VERSION "created by canmatrix"

NS_ :

BS_:

BU_: User ADM_PC_LL25 ADM_PC_BC25 ADM_PC_BP25 ADM_PC_BI25

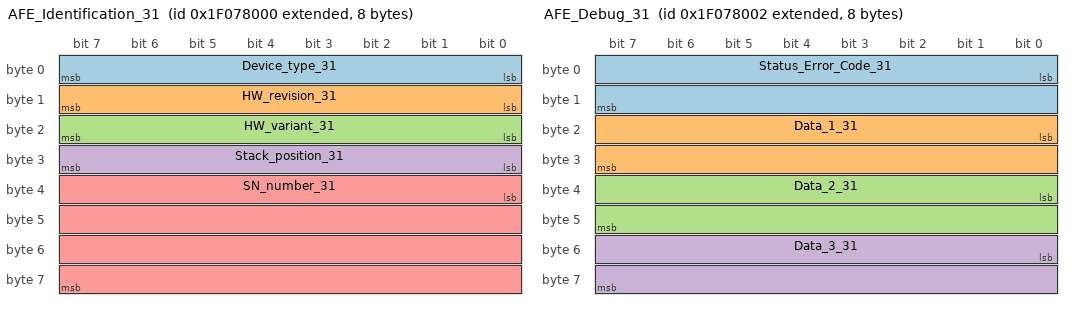
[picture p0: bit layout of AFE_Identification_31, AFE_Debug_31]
BO_ 2668068864 AFE_Identification_31: 8 ADM_PC_BP25
 SG_ Device_type_31 : 0|8@1+ (1,0) [0|255] "" Vector__XXX
 SG_ HW_revision_31 : 8|8@1+ (1,0) [0|255] "" Vector__XXX
 SG_ HW_variant_31 : 16|8@1+ (1,0) [0|255] "" Vector__XXX
 SG_ Stack_position_31 : 24|8@1+ (1,0) [0|255] "" Vector__XXX
 SG_ SN_number_31 : 32|32@1+ (1,0) [0|4294967295] "" Vector__XXX

BO_ 2668068865 AFE_FwInfo_31: 8 ADM_PC_BP25
 SG_ FW_info_mux_31 M : 56|8@1+ (1,0) [0|255] "" Vector__XXX
 SG_ FW_revision_0_31 m0 : 0|8@1+ (1,0) [0|255] "" Vector__XXX
 SG_ FW_revision_1_31 m0 : 8|8@1+ (1,0) [0|255] "" Vector__XXX
 SG_ FW_revision_2_31 m0 : 16|8@1+ (1,0) [0|255] "" Vector__XXX
 SG_ FW_revision_3_31 m0 : 24|8@1+ (1,0) [0|255] "" Vector__XXX
 SG_ FW_revision_4_31 m0 : 32|8@1+ (1,0) [0|255] "" Vector__XXX
 SG_ FW_revision_5_31 m0 : 40|8@1+ (1,0) [0|255] "" Vector__XXX
 SG_ FW_revision_6_31 m0 : 48|8@1+ (1,0) [0|255] "" Vector__XXX
 SG_ FW_revision_7_31 m1 : 0|8@1+ (1,0) [0|255] "" Vector__XXX
 SG_ FW_revision_8_31 m1 : 8|8@1+ (1,0) [0|255] "" Vector__XXX
 SG_ FW_revision_9_31 m1 : 16|8@1+ (1,0) [0|255] "" Vector__XXX
 SG_ FW_revision_10_31 m1 : 24|8@1+ (1,0) [0|255] "" Vector__XXX
 SG_ FW_revision_11_31 m1 : 32|8@1+ (1,0) [0|255] "" Vector__XXX
 SG_ FW_revision_12_31 m1 : 40|8@1+ (1,0) [0|255] "" Vector__XXX
 SG_ FW_revision_13_31 m1 : 48|8@1+ (1,0) [0|255] "" Vector__XXX
 SG_ FW_datecode_0_31 m2 : 0|8@1+ (1,0) [0|255] "" Vector__XXX
 SG_ FW_datecode_1_31 m2 : 8|8@1+ (1,0) [0|255] "" Vector__XXX
 SG_ FW_datecode_2_31 m2 : 16|8@1+ (1,0) [0|255] "" Vector__XXX
 SG_ FW_datecode_3_31 m2 : 24|8@1+ (1,0) [0|255] "" Vector__XXX
 SG_ FW_datecode_4_31 m2 : 32|8@1+ (1,0) [0|255] "" Vector__XXX
 SG_ FW_datecode_5_31 m2 : 40|8@1+ (1,0) [0|255] "" Vector__XXX
 SG_ FW_datecode_6_31 m2 : 48|8@1+ (1,0) [0|255] "" Vector__XXX
 SG_ FW_datecode_7_31 m3 : 0|8@1+ (1,0) [0|255] "" Vector__XXX
 SG_ FW_datecode_8_31 m3 : 8|8@1+ (1,0) [0|255] "" Vector__XXX
 SG_ FW_datecode_9_31 m3 : 16|8@1+ (1,0) [0|255] "" Vector__XXX
 SG_ FW_datecode_10_31 m3 : 24|8@1+ (1,0) [0|255] "" Vector__XXX
 SG_ FW_datecode_11_31 m3 : 32|8@1+ (1,0) [0|255] "" Vector__XXX
 SG_ FW_datecode_12_31 m3 : 40|8@1+ (1,0) [0|255] "" Vector__XXX
 SG_ FW_datecode_13_31 m3 : 48|8@1+ (1,0) [0|255] "" Vector__XXX

BO_ 2668068877 _AFE_Boot_FwInfo_31: 8 ADM_PC_BP25
 SG_ Boot_FW_info_mux_31 M : 56|8@1+ (1,0) [0|255] "" Vector__XXX
 SG_ FW_revision_0_31 m0 : 0|8@1+ (1,0) [0|255] "" Vector__XXX
 SG_ FW_revision_1_31 m0 : 8|8@1+ (1,0) [0|255] "" Vector__XXX
 SG_ FW_revision_2_31 m0 : 16|8@1+ (1,0) [0|255] "" Vector__XXX
 SG_ FW_revision_3_31 m0 : 24|8@1+ (1,0) [0|255] "" Vector__XXX
 SG_ FW_revision_4_31 m0 : 32|8@1+ (1,0) [0|255] "" Vector__XXX
 SG_ FW_revision_5_31 m0 : 40|8@1+ (1,0) [0|255] "" Vector__XXX
 SG_ FW_revision_6_31 m0 : 48|8@1+ (1,0) [0|255] "" Vector__XXX
 SG_ FW_revision_7_31 m1 : 0|8@1+ (1,0) [0|255] "" Vector__XXX
 SG_ FW_revision_8_31 m1 : 8|8@1+ (1,0) [0|255] "" Vector__XXX
 SG_ FW_revision_9_31 m1 : 16|8@1+ (1,0) [0|255] "" Vector__XXX
 SG_ FW_revision_10_31 m1 : 24|8@1+ (1,0) [0|255] "" Vector__XXX
 SG_ FW_revision_11_31 m1 : 32|8@1+ (1,0) [0|255] "" Vector__XXX
 SG_ FW_revision_12_31 m1 : 40|8@1+ (1,0) [0|255] "" Vector__XXX
 SG_ FW_revision_13_31 m1 : 48|8@1+ (1,0) [0|255] "" Vector__XXX
 SG_ FW_datecode_0_31 m2 : 0|8@1+ (1,0) [0|255] "" Vector__XXX
 SG_ FW_datecode_1_31 m2 : 8|8@1+ (1,0) [0|255] "" Vector__XXX
 SG_ FW_datecode_2_31 m2 : 16|8@1+ (1,0) [0|255] "" Vector__XXX
 SG_ FW_datecode_3_31 m2 : 24|8@1+ (1,0) [0|255] "" Vector__XXX
 SG_ FW_datecode_4_31 m2 : 32|8@1+ (1,0) [0|255] "" Vector__XXX
 SG_ FW_datecode_5_31 m2 : 40|8@1+ (1,0) [0|255] "" Vector__XXX
 SG_ FW_datecode_6_31 m2 : 48|8@1+ (1,0) [0|255] "" Vector__XXX
 SG_ FW_datecode_7_31 m3 : 0|8@1+ (1,0) [0|255] "" Vector__XXX
 SG_ FW_datecode_8_31 m3 : 8|8@1+ (1,0) [0|255] "" Vector__XXX
 SG_ FW_datecode_9_31 m3 : 16|8@1+ (1,0) [0|255] "" Vector__XXX
 SG_ FW_datecode_10_31 m3 : 24|8@1+ (1,0) [0|255] "" Vector__XXX
 SG_ FW_datecode_11_31 m3 : 32|8@1+ (1,0) [0|255] "" Vector__XXX
 SG_ FW_datecode_12_31 m3 : 40|8@1+ (1,0) [0|255] "" Vector__XXX
 SG_ FW_datecode_13_31 m3 : 48|8@1+ (1,0) [0|255] "" Vector__XXX

BO_ 2668068866 AFE_Debug_31: 8 ADM_PC_BP25
 SG_ Status_Error_Code_31 : 0|16@1+ (1,0) [0|65535] "" Vector__XXX
 SG_ Data_1_31 : 16|16@1+ (1,0) [0|65535] "" Vector__XXX
 SG_ Data_2_31 : 32|16@1+ (1,0) [0|65535] "" Vector__XXX
 SG_ Data_3_31 : 48|16@1+ (1,0) [0|65535] "" Vector__XXX

BO_ 2668068871 AFE_Status_31: 8 ADM_PC_BP25
 SG_ Running_31 : 0|1@1+ (1,0) [0|1] "" Vector__XXX
 SG_ PWM_31 : 1|1@1+ (1,0) [0|1] "" Vector__XXX
 SG_ Current_dc_loop_mode_31 : 2|1@1+ (1,0) [0|1] "" Vector__XXX
 SG_ Current_ac_loop_mode_31 : 3|1@1+ (1,0) [0|1] "" Vector__XXX
 SG_ Buck_31 : 5|1@1+ (1,0) [0|1] "" Vector__XXX
 SG_ Boost_31 : 6|1@1+ (1,0) [0|1] "" Vector__XXX
 SG_ Precharge_dc_buck_mode_31 : 7|1@1+ (1,0) [0|1] "" Vector__XXX
 SG_ Precharge_dc_boost_mode_31 : 8|1@1+ (1,0) [0|1] "" Vector__XXX
 SG_ Rectifier_3ph_31 : 9|1@1+ (1,0) [0|1] "" Vector__XXX
 SG_ Stack_mode_31 : 10|1@1+ (1,0) [0|1] "" Vector__XXX
 SG_ Master_31 : 11|1@1+ (1,0) [0|1] "" Vector__XXX
 SG_ Slave_31 : 12|1@1+ (1,0) [0|1] "" Vector__XXX
 SG_ Inverter_1ph_31 : 13|1@1+ (1,0) [0|1] "" Vector__XXX
 SG_ Boost_Neutral_31 : 14|1@1+ (1,0) [0|1] "" Vector__XXX
 SG_ Rectifier_1ph_31 : 15|1@1+ (1,0) [0|1] "" Vector__XXX
 SG_ Inverter_3ph_31 : 16|1@1+ (1,0) [0|1] "" Vector__XXX
 SG_ Ready_31 : 17|1@1+ (1,0) [0|1] "" Vector__XXX
 SG_ Inverter_1ph_Sync_31 : 18|1@1+ (1,0) [0|1] "" Vector__XXX
 SG_ Neutral_31 : 19|1@1+ (1,0) [0|1] "" Vector__XXX
 SG_ Rectifier_1ph_Buck_31 : 20|1@1+ (1,0) [0|1] "" Vector__XXX
 SG_ Inverter_1ph_Boost_31 : 21|1@1+ (1,0) [0|1] "" Vector__XXX
 SG_ Rectifier_distributed_31 : 22|1@1+ (1,0) [0|1] "" Vector__XXX
 SG_ MPPT_buck_31 : 23|1@1+ (1,0) [0|1] "" Vector__XXX
 SG_ MPPT_boost_31 : 24|1@1+ (1,0) [0|1] "" Vector__XXX
 SG_ Buck_2p_float_31 : 25|1@1+ (1,0) [0|1] "" Vector__XXX
 SG_ Inverter_1ph_Distributed_31 : 26|1@1+ (1,0) [0|1] "" Vector__XXX

BO_ 2668068870 AFE_Faults_31: 3 ADM_PC_BP25
 SG_ Protection_trip_internal_31 : 0|1@1+ (1,0) [0|1] "" Vector__XXX
 SG_ Protection_trip_external_31 : 1|1@1+ (1,0) [0|1] "" Vector__XXX
 SG_ Phase_U_overcurrent_31 : 2|1@1+ (1,0) [0|1] "" Vector__XXX
 SG_ Phase_U_overvoltage_31 : 3|1@1+ (1,0) [0|1] "" Vector__XXX
 SG_ Phase_U_undervoltage_31 : 4|1@1+ (1,0) [0|1] "" Vector__XXX
 SG_ Phase_V_overvoltage_31 : 5|1@1+ (1,0) [0|1] "" Vector__XXX
 SG_ Phase_V_undervoltage_31 : 6|1@1+ (1,0) [0|1] "" Vector__XXX
 SG_ Phase_V_overcurrent_31 : 7|1@1+ (1,0) [0|1] "" Vector__XXX
 SG_ Phase_W_overvoltage_31 : 8|1@1+ (1,0) [0|1] "" Vector__XXX
 SG_ Phase_W_undervoltage_31 : 9|1@1+ (1,0) [0|1] "" Vector__XXX
 SG_ Phase_W_overcurrent_31 : 10|1@1+ (1,0) [0|1] "" Vector__XXX
 SG_ DC_undervoltage_31 : 11|1@1+ (1,0) [0|1] "" Vector__XXX
 SG_ DC_overvoltage_31 : 12|1@1+ (1,0) [0|1] "" Vector__XXX
 SG_ MOSFET_overtemperature_31 : 13|1@1+ (1,0) [0|1] "" Vector__XXX
 SG_ Inductor_overtemperature_31 : 14|1@1+ (1,0) [0|1] "" Vector__XXX
 SG_ Keep_Alive_not_served_31 : 15|1@1+ (1,0) [0|1] "" Vector__XXX
 SG_ PLL_not_locked_31 : 16|1@1+ (1,0) [0|1] "" Vector__XXX
 SG_ NFO_31 : 20|1@1+ (1,0) [0|1] "" Vector__XXX
 SG_ Measurement_system_failure_31 : 21|1@1+ (1,0) [0|1] "" Vector__XXX
 SG_ EEPROM_failure_31 : 22|1@1+ (1,0) [0|1] "" Vector__XXX
 SG_ System_31 : 23|1@1+ (1,0) [0|1] "" Vector__XXX

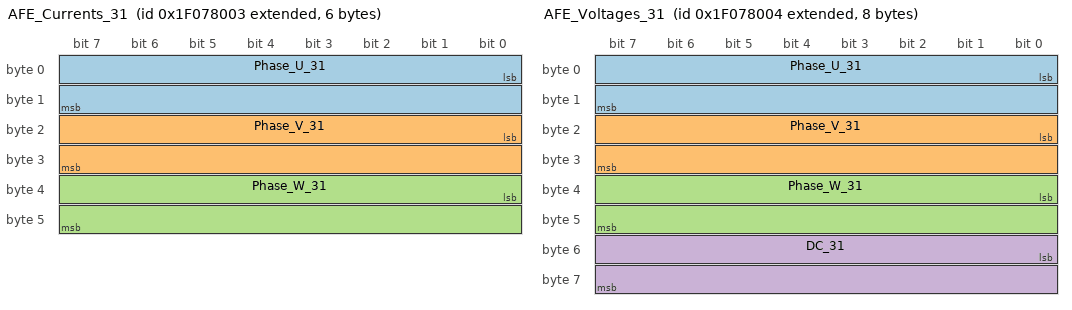
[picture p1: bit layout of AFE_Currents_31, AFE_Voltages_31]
BO_ 2668068867 AFE_Currents_31: 6 ADM_PC_BP25
 SG_ Phase_U_31 : 0|16@1- (0.01,0) [-327.68|327.67] "A" Vector__XXX
 SG_ Phase_V_31 : 16|16@1- (0.01,0) [-327.68|327.67] "A" Vector__XXX
 SG_ Phase_W_31 : 32|16@1- (0.01,0) [-327.68|327.67] "A" Vector__XXX

BO_ 2668068880 AFE_DC_Bus_current_31: 2 ADM_PC_BP25
 SG_ Bus_current_31 : 0|16@1- (0.01,0) [-327.68|327.67] "A" Vector__XXX

BO_ 2668068878 _AFE_Broadcast_31: 8 ADM_PC_BP25
 SG_ Diagnostics_Index_31 M : 56|8@1+ (1,0) [0|255] "" Vector__XXX
 SG_ Phase_U_31 m1 : 8|16@1- (0.01,0) [-327.68|327.67] "A" ADM_PC_BP25
 SG_ Phase_V_31 m1 : 24|16@1- (0.01,0) [-327.68|327.67] "A" ADM_PC_BP25
 SG_ Phase_W_31 m1 : 40|16@1- (0.01,0) [-327.68|327.67] "A" ADM_PC_BP25
 SG_ Stack_position_31 : 0|5@1+ (1,0) [0|31] "" ADM_PC_BP25
 SG_ Group_ID_31 : 5|3@1+ (1,0) [0|7] "" ADM_PC_BP25

BO_ 2668068868 AFE_Voltages_31: 8 ADM_PC_BP25
 SG_ Phase_U_31 : 0|16@1- (0.1,0) [-3276.8|3276.7] "V" Vector__XXX
 SG_ Phase_V_31 : 16|16@1- (0.1,0) [-3276.8|3276.7] "V" Vector__XXX
 SG_ Phase_W_31 : 32|16@1- (0.1,0) [-3276.8|3276.7] "V" Vector__XXX
 SG_ DC_31 : 48|16@1- (0.1,0) [-3276.8|3276.7] "V" Vector__XXX

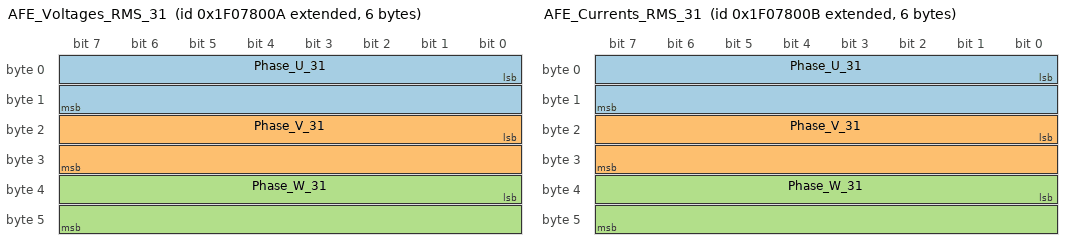
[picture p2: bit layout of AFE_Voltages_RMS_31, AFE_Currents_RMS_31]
BO_ 2668068874 AFE_Voltages_RMS_31: 6 ADM_PC_BP25
 SG_ Phase_U_31 : 0|16@1+ (0.1,0) [0|6553.5] "V" Vector__XXX
 SG_ Phase_V_31 : 16|16@1+ (0.1,0) [0|6553.5] "V" Vector__XXX
 SG_ Phase_W_31 : 32|16@1+ (0.1,0) [0|6553.5] "V" Vector__XXX

BO_ 2668068875 AFE_Currents_RMS_31: 6 ADM_PC_BP25
 SG_ Phase_U_31 : 0|16@1+ (0.01,0) [0.00|655.35] "A" Vector__XXX
 SG_ Phase_V_31 : 16|16@1+ (0.01,0) [0.00|655.35] "A" Vector__XXX
 SG_ Phase_W_31 : 32|16@1+ (0.01,0) [0.00|655.35] "A" Vector__XXX

BO_ 2668068876 AFE_Mains_31: 4 ADM_PC_BP25
 SG_ Frequency_31 : 0|16@1+ (0.01,0) [0.00|655.35] "Hz" Vector__XXX
 SG_ Phase_31 : 16|16@1- (0.1,0) [-3276.8|3276.7] "Deg." Vector__XXX

BO_ 2668068869 AFE_Temperatures_31: 4 ADM_PC_BP25
 SG_ Temp_Bridge_31 : 0|16@1- (0.01,0) [-327.68|327.67] "°C" Vector__XXX
 SG_ Temp_Inductors_31 : 16|16@1- (0.01,0) [-327.68|327.67] "°C" Vector__XXX

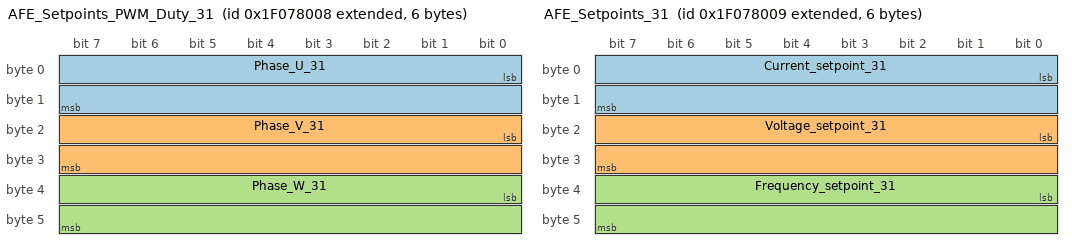
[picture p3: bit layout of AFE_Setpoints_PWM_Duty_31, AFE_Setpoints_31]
BO_ 2668068872 AFE_Setpoints_PWM_Duty_31: 6 ADM_PC_BP25
 SG_ Phase_U_31 : 0|16@1+ (0.001525902,0) [0E-009|99.999987570] "%" Vector__XXX
 SG_ Phase_V_31 : 16|16@1+ (0.001525902,0) [0E-009|99.999987570] "%" Vector__XXX
 SG_ Phase_W_31 : 32|16@1+ (0.001525902,0) [0E-009|99.999987570] "%" Vector__XXX

BO_ 2668068873 AFE_Setpoints_31: 6 ADM_PC_BP25
 SG_ Current_setpoint_31 : 0|16@1- (0.01,0) [-327.68|327.67] "A" Vector__XXX
 SG_ Voltage_setpoint_31 : 16|16@1+ (0.1,0) [0|6553.5] "V" Vector__XXX
 SG_ Frequency_setpoint_31 : 32|16@1+ (0.01,0) [0.00|655.35] "Hz" Vector__XXX

BO_ 2668036192 AFE_Keep_Alive_31: 1 User
 SG_ Keep_Alive_Enable_31 : 0|1@1+ (1,0) [0|1] "" ADM_PC_BP25

BO_ 2668036160 AFE_Mode_Control_31: 8 User
 SG_ Converter_ON_31 : 0|1@1+ (1,0) [0|1] "" ADM_PC_BP25
 SG_ PWM_ON_31 : 1|1@1+ (1,0) [0|1] "" ADM_PC_BP25
 SG_ DC_Current_feedback_ON_31 : 2|1@1+ (1,0) [0|1] "" ADM_PC_BP25
 SG_ AC_Current_feedback_ON_31 : 3|1@1+ (1,0) [0|1] "" ADM_PC_BP25
 SG_ Buck_ON_31 : 5|1@1+ (1,0) [0|1] "" ADM_PC_BP25
 SG_ Boost_ON_31 : 6|1@1+ (1,0) [0|1] "" ADM_PC_BP25
 SG_ Rectifier_3ph_ON_31 : 9|1@1+ (1,0) [0|1] "" ADM_PC_BP25
 SG_ Inverter_1ph_ON_31 : 10|1@1+ (1,0) [0|1] "" ADM_PC_BP25
 SG_ Rectifier_1ph_ON_31 : 11|1@1+ (1,0) [0|1] "" ADM_PC_BP25
 SG_ Boost_Neutral_ON_31 : 12|1@1+ (1,0) [0|1] "" ADM_PC_BP25
 SG_ Inverter_3ph_ON_31 : 13|1@1+ (1,0) [0|1] "" ADM_PC_BP25
 SG_ Inverter_1ph_Sync_ON_31 : 14|1@1+ (1,0) [0|1] "" ADM_PC_BP25
 SG_ Neutral_ON_31 : 15|1@1+ (1,0) [0|1] "" ADM_PC_BP25
 SG_ Rectifier_1ph_Buck_ON_31 : 16|1@1+ (1,0) [0|1] "" ADM_PC_BP25
 SG_ Inverter_1ph_Boost_ON_31 : 17|1@1+ (1,0) [0|1] "" ADM_PC_BP25
 SG_ Rectifier_Distributed_ON_31 : 18|1@1+ (1,0) [0|1] "" ADM_PC_BP25
 SG_ MPPT_buck_ON_31 : 19|1@1+ (1,0) [0|1] "" ADM_PC_BP25
 SG_ MPPT_boost_ON_31 : 20|1@1+ (1,0) [0|1] "" ADM_PC_BP25
 SG_ Buck_2p_float_ON_31 : 21|1@1+ (1,0) [0|1] "" ADM_PC_BP25
 SG_ Inverter_1ph_Distributed_ON_31 : 22|1@1+ (1,0) [0|1] "" ADM_PC_BP25

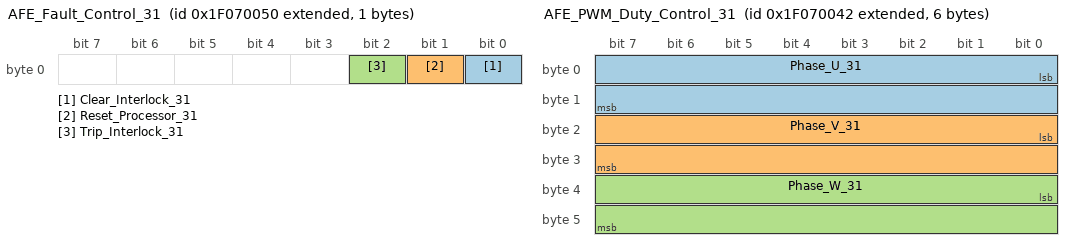
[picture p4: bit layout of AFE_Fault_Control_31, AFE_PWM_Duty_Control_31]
BO_ 2668036176 AFE_Fault_Control_31: 1 User
 SG_ Clear_Interlock_31 : 0|1@1+ (1,0) [0|1] "" ADM_PC_BP25
 SG_ Reset_Processor_31 : 1|1@1+ (1,0) [0|1] "" ADM_PC_BP25
 SG_ Trip_Interlock_31 : 2|1@1+ (1,0) [0|1] "" ADM_PC_BP25

BO_ 2668036161 AFE_Reactive_Current_Setpoint_Co: 2 User
 SG_ Reactive_current_setpoint_31 : 0|16@1- (0.01,0) [-150|150] "A" ADM_PC_BP25

BO_ 2668036162 AFE_PWM_Duty_Control_31: 6 User
 SG_ Phase_U_31 : 0|16@1+ (0.001525902,0) [0E-009|99.999987570] "%" ADM_PC_BP25
 SG_ Phase_V_31 : 16|16@1+ (0.001525902,0) [0E-009|99.999987570] "%" ADM_PC_BP25
 SG_ Phase_W_31 : 32|16@1+ (0.001525902,0) [0E-009|99.999987570] "%" ADM_PC_BP25

BO_ 2668036163 AFE_Current_Setpoint_Control_31: 2 User
 SG_ Current_setpoint_31 : 0|16@1- (0.01,0) [-150|150] "A" ADM_PC_BP25

BO_ 2668036164 AFE_Voltage_Setpoint_Control_31: 2 User
 SG_ Voltage_setpoint_31 : 0|16@1+ (0.1,0) [0|1500] "V" ADM_PC_BP25

BO_ 2668036168 AFE_Frequency_Setpoint_Control_3: 2 User
 SG_ Frequency_setpoint_31 : 0|16@1+ (0.01,0) [40|70] "Hz" ADM_PC_BP25

BO_ 2668036169 AFE_Phase_Setpoint_Control_31: 2 User
 SG_ Phase_setpoint_31 : 0|16@1+ (1,0) [0|360] "deg" ADM_PC_BP25

BO_ 2668036208 AFE_Rectifier_Setpoint_Control_3: 8 User
 SG_ Voltage_setpoint_2_31 : 0|16@1+ (0.1,0) [0|1500] "V" ADM_PC_BP25
 SG_ Current_setpoint_2_31 : 16|16@1- (0.01,0) [-150|150] "A" ADM_PC_BP25

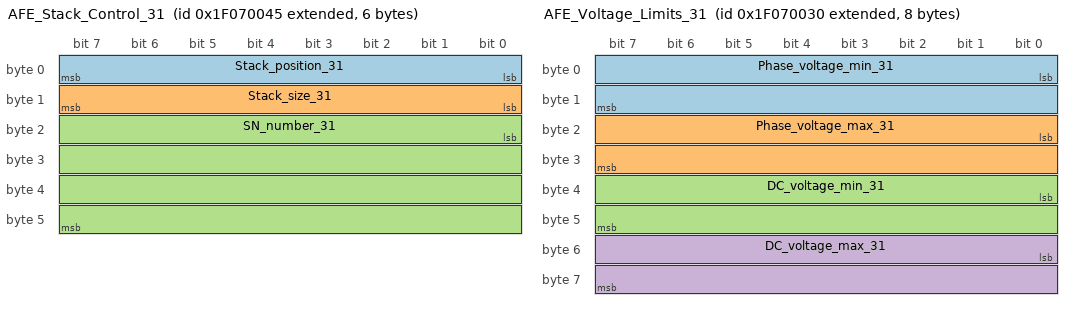
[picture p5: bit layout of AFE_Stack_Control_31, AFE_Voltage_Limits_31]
BO_ 2668036165 AFE_Stack_Control_31: 6 User
 SG_ Stack_position_31 : 0|8@1+ (1,0) [0|255] "" ADM_PC_BP25
 SG_ Stack_size_31 : 8|8@1+ (1,0) [0|255] "" ADM_PC_BP25
 SG_ SN_number_31 : 16|32@1+ (1,0) [0|4294967295] "" ADM_PC_BP25

BO_ 2668036144 AFE_Voltage_Limits_31: 8 User
 SG_ Phase_voltage_min_31 : 0|16@1- (0.1,0) [0|3276.7] "V" ADM_PC_BP25
 SG_ Phase_voltage_max_31 : 16|16@1- (0.1,0) [-3276.8|850] "V" ADM_PC_BP25
 SG_ DC_voltage_min_31 : 32|16@1- (0.1,0) [0|3276.7] "V" ADM_PC_BP25
 SG_ DC_voltage_max_31 : 48|16@1- (0.1,0) [-3276.8|850] "V" ADM_PC_BP25

BO_ 2668036145 AFE_Current_Limits_31: 4 User
 SG_ Phase_current_min_31 : 0|16@1- (0.01,0) [-60|60] "A" ADM_PC_BP25
 SG_ Phase_current_max_31 : 16|16@1- (0.01,0) [-60|60] "A" ADM_PC_BP25

BO_ 2668036172 AFE_Group_Control_31: 1 User
 SG_ Group_ID_31 : 0|8@1+ (1,0) [0|255] "" ADM_PC_BP25

BO_ 2668068879 AFE_Group_Info_31: 1 ADM_PC_BP25
 SG_ Group_ID_31 : 0|8@1+ (1,0) [0|255] "" Vector__XXX

BO_ 2668036193 AFE_System_Flags_Control_31: 8 User
 SG_ Factory_mode_31 : 0|1@1+ (1,0) [0|1] "" ADM_PC_BP25
 SG_ Silent_CAN_mode_31 : 1|1@1+ (1,0) [0|1] "" ADM_PC_BP25

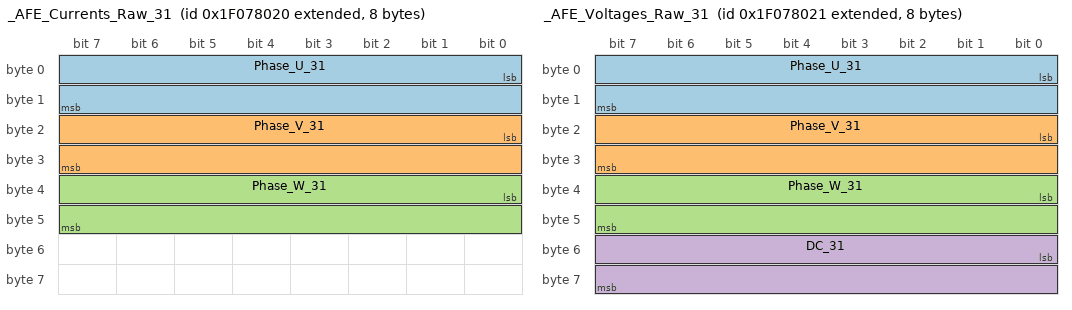
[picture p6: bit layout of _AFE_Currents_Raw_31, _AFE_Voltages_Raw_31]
BO_ 2668068896 _AFE_Currents_Raw_31: 8 ADM_PC_BP25
 SG_ Phase_U_31 : 0|16@1- (1,0) [-32768|32767] "" Vector__XXX
 SG_ Phase_V_31 : 16|16@1- (1,0) [-32768|32767] "" Vector__XXX
 SG_ Phase_W_31 : 32|16@1- (1,0) [-32768|32767] "" Vector__XXX

BO_ 2668068897 _AFE_Voltages_Raw_31: 8 ADM_PC_BP25
 SG_ Phase_U_31 : 0|16@1- (1,0) [-32768|32767] "" Vector__XXX
 SG_ Phase_V_31 : 16|16@1- (1,0) [-32768|32767] "" Vector__XXX
 SG_ Phase_W_31 : 32|16@1- (1,0) [-32768|32767] "" Vector__XXX
 SG_ DC_31 : 48|16@1- (1,0) [-32768|32767] "" Vector__XXX

BO_ 2668036170 _AFE_ADC_Calibration_Mode_31: 1 User
 SG_ Calibration_Index_31 M : 2|5@1+ (1,0) [0|31] "" Vector__XXX
 SG_ Current_U_31 m1 : 0|2@1+ (1,0) [0|3] "" ADM_PC_BP25
 SG_ Current_V_31 m2 : 0|2@1+ (1,0) [0|3] "" ADM_PC_BP25
 SG_ Current_W_31 m3 : 0|2@1+ (1,0) [0|3] "" ADM_PC_BP25
 SG_ Voltage_U_31 m4 : 0|2@1+ (1,0) [0|3] "" ADM_PC_BP25
 SG_ Voltage_V_31 m5 : 0|2@1+ (1,0) [0|3] "" ADM_PC_BP25
 SG_ Voltage_W_31 m6 : 0|2@1+ (1,0) [0|3] "" ADM_PC_BP25
 SG_ Voltage_DC_31 m7 : 0|2@1+ (1,0) [0|3] "" ADM_PC_BP25
 SG_ start_31 : 7|1@1+ (1,0) [0|1] "" ADM_PC_BP25

BO_ 2668036171 _AFE_ADC_Calibration_Setpoint_31: 3 User
 SG_ Calibration_Index_31 M : 16|5@1+ (1,0) [0|31] "" Vector__XXX
 SG_ Current_U_31 m1 : 0|16@1- (0.01,0) [-100|100] "A" ADM_PC_BP25
 SG_ Current_V_31 m2 : 0|16@1- (0.01,0) [-100|100] "A" ADM_PC_BP25
 SG_ Current_W_31 m3 : 0|16@1- (0.01,0) [-100|100] "A" ADM_PC_BP25
 SG_ Voltage_U_31 m4 : 0|16@1+ (0.1,0) [0|1500] "V" ADM_PC_BP25
 SG_ Voltage_V_31 m5 : 0|16@1+ (0.1,0) [0|1500] "V" ADM_PC_BP25
 SG_ Voltage_W_31 m6 : 0|16@1+ (0.1,0) [0|1500] "V" ADM_PC_BP25
 SG_ Voltage_DC_31 m7 : 0|16@1+ (0.1,0) [0|1500] "V" ADM_PC_BP25
 SG_ point_31 : 21|3@1+ (1,0) [0|7] "" ADM_PC_BP25

BO_ 2668036166 _AFE_Calibration_Offset_Update_3: 6 User
 SG_ Calibration_Index_31 M : 16|16@1+ (1,0) [0|65535] "" Vector__XXX
 SG_ Current_U_31 m0 : 0|16@1- (1,0) [-32768|32767] "ADC Counts" ADM_PC_BP25
 SG_ Current_V_31 m1 : 0|16@1- (1,0) [-32768|32767] "ADC Counts" ADM_PC_BP25
 SG_ Current_W_31 m2 : 0|16@1- (1,0) [-32768|32767] "ADC Counts" ADM_PC_BP25
 SG_ Voltage_U_31 m3 : 0|16@1- (1,0) [-32768|32767] "ADC Counts" ADM_PC_BP25
 SG_ Voltage_V_31 m4 : 0|16@1- (1,0) [-32768|32767] "ADC Counts" ADM_PC_BP25
 SG_ Voltage_W_31 m5 : 0|16@1- (1,0) [-32768|32767] "ADC Counts" ADM_PC_BP25
 SG_ Voltage_DC_31 m6 : 0|16@1- (1,0) [-32768|32767] "ADC Counts" ADM_PC_BP25
 SG_ CRC_31 : 32|16@1+ (1,0) [0|65535] "-" ADM_PC_BP25

BO_ 2668036167 _AFE_Calibration_Scale_Update_31: 6 User
 SG_ Calibration_Index_31 M : 16|16@1+ (1,0) [0|65535] "" Vector__XXX
 SG_ Current_U_31 m0 : 0|16@1- (0.0000152587890625,0) [-0.5000000000000000|0.4999847412109375] "scale = 1.0 + value" ADM_PC_BP25
 SG_ Current_V_31 m1 : 0|16@1- (0.0000152587890625,0) [-0.5000000000000000|0.4999847412109375] "scale = 1.0 + value" ADM_PC_BP25
 SG_ Current_W_31 m2 : 0|16@1- (0.0000152587890625,0) [-0.5000000000000000|0.4999847412109375] "scale = 1.0 + value" ADM_PC_BP25
 SG_ Voltage_U_31 m3 : 0|16@1- (0.0000152587890625,0) [-0.5000000000000000|0.4999847412109375] "scale = 1.0 + value" ADM_PC_BP25
 SG_ Voltage_V_31 m4 : 0|16@1- (0.0000152587890625,0) [-0.5000000000000000|0.4999847412109375] "scale = 1.0 + value" ADM_PC_BP25
 SG_ Voltage_W_31 m5 : 0|16@1- (0.0000152587890625,0) [-0.5000000000000000|0.4999847412109375] "scale = 1.0 + value" ADM_PC_BP25
 SG_ Voltage_DC_31 m6 : 0|16@1- (0.0000152587890625,0) [-0.5000000000000000|0.4999847412109375] "scale = 1.0 + value" ADM_PC_BP25
 SG_ CRC_31 : 32|16@1+ (1,0) [0|65535] "-" ADM_PC_BP25

BO_ 2668068945 _AFE_Calibration_Adc_Scale_31: 6 ADM_PC_BP25
 SG_ Adc_Index_31 M : 32|16@1+ (1,0) [0|65535] "" Vector__XXX
 SG_ Current_U_31 m0 : 0|32@1+ (1,0) [0|4294967295] "1 / adc_bins" User
 SG_ Current_V_31 m1 : 0|32@1+ (1,0) [0|4294967295] "1 / adc_bins" User
 SG_ Current_W_31 m2 : 0|32@1+ (1,0) [0|4294967295] "1 / adc_bins" User
 SG_ Voltage_U_31 m3 : 0|32@1+ (1,0) [0|4294967295] "1 / adc_bins" User
 SG_ Voltage_V_31 m4 : 0|32@1+ (1,0) [0|4294967295] "1 / adc_bins" User
 SG_ Voltage_W_31 m5 : 0|32@1+ (1,0) [0|4294967295] "1 / adc_bins" User
 SG_ Voltage_DC_31 m6 : 0|32@1+ (1,0) [0|4294967295] "1 / adc_bins" User

BO_ 2668068946 _AFE_Calibration_Adc_Fs_31: 6 ADM_PC_BP25
 SG_ Adc_Index_31 M : 32|16@1+ (1,0) [0|65535] "" Vector__XXX
 SG_ Current_U_31 m0 : 0|32@1+ (1,0) [0|4294967295] "Fullscale" User
 SG_ Current_V_31 m1 : 0|32@1+ (1,0) [0|4294967295] "Fullscale" User
 SG_ Current_W_31 m2 : 0|32@1+ (1,0) [0|4294967295] "Fullscale" User
 SG_ Voltage_U_31 m3 : 0|32@1+ (1,0) [0|4294967295] "Fullscale" User
 SG_ Voltage_V_31 m4 : 0|32@1+ (1,0) [0|4294967295] "Fullscale" User
 SG_ Voltage_W_31 m5 : 0|32@1+ (1,0) [0|4294967295] "Fullscale" User
 SG_ Voltage_DC_31 m6 : 0|32@1+ (1,0) [0|4294967295] "Fullscale" User

BO_ 2668068947 _AFE_Calibration_Adc_Offset_31: 4 ADM_PC_BP25
 SG_ Adc_Index_31 M : 16|16@1+ (1,0) [0|65535] "" Vector__XXX
 SG_ Current_U_31 m0 : 0|16@1- (1,0) [-32768|32767] "-" User
 SG_ Current_V_31 m1 : 0|16@1- (1,0) [-32768|32767] "-" User
 SG_ Current_W_31 m2 : 0|16@1- (1,0) [-32768|32767] "-" User
 SG_ Voltage_U_31 m3 : 0|16@1- (1,0) [-32768|32767] "-" User
 SG_ Voltage_V_31 m4 : 0|16@1- (1,0) [-32768|32767] "-" User
 SG_ Voltage_W_31 m5 : 0|16@1- (1,0) [-32768|32767] "-" User
 SG_ Voltage_DC_31 m6 : 0|16@1- (1,0) [-32768|32767] "-" User

BO_ 2668068948 _AFE_Calibration_Adc_Gain_31: 4 ADM_PC_BP25
 SG_ Adc_Index_31 M : 16|16@1+ (1,0) [0|65535] "" Vector__XXX
 SG_ Current_U_31 m0 : 0|16@1- (1,0) [-32768|32767] "-" User
 SG_ Current_V_31 m1 : 0|16@1- (1,0) [-32768|32767] "-" User
 SG_ Current_W_31 m2 : 0|16@1- (1,0) [-32768|32767] "-" User
 SG_ Voltage_U_31 m3 : 0|16@1- (1,0) [-32768|32767] "-" User
 SG_ Voltage_V_31 m4 : 0|16@1- (1,0) [-32768|32767] "-" User
 SG_ Voltage_W_31 m5 : 0|16@1- (1,0) [-32768|32767] "-" User
 SG_ Voltage_DC_31 m6 : 0|16@1- (1,0) [-32768|32767] "-" User

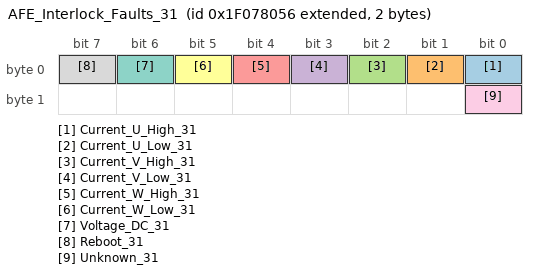
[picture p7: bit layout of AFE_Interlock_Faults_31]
BO_ 2668068950 AFE_Interlock_Faults_31: 2 ADM_PC_BP25
 SG_ Current_U_High_31 : 0|1@1+ (1,0) [0|1] "" Vector__XXX
 SG_ Current_U_Low_31 : 1|1@1+ (1,0) [0|1] "" Vector__XXX
 SG_ Current_V_High_31 : 2|1@1+ (1,0) [0|1] "" Vector__XXX
 SG_ Current_V_Low_31 : 3|1@1+ (1,0) [0|1] "" Vector__XXX
 SG_ Current_W_High_31 : 4|1@1+ (1,0) [0|1] "" Vector__XXX
 SG_ Current_W_Low_31 : 5|1@1+ (1,0) [0|1] "" Vector__XXX
 SG_ Voltage_DC_31 : 6|1@1+ (1,0) [0|1] "" Vector__XXX
 SG_ Reboot_31 : 7|1@1+ (1,0) [0|1] "" Vector__XXX
 SG_ Unknown_31 : 8|1@1+ (1,0) [0|1] "" Vector__XXX

BO_TX_BU_ 2668036160 : User,ADM_PC_LL25,ADM_PC_BC25,ADM_PC_BI25;
BO_TX_BU_ 2668036163 : User,ADM_PC_LL25,ADM_PC_BC25,ADM_PC_BI25;
BO_TX_BU_ 2668036164 : User,ADM_PC_LL25,ADM_PC_BC25,ADM_PC_BI25;
CM_ BO_ 2668068864  "Identification of the device";
CM_ BO_ 2668068865  "Git revision of the DSP firmware";
CM_ BO_ 2668068877  "Git revision of the bootloader firmware.";
CM_ BO_ 2668068866  "Values for debugging of HW/SW problems";
CM_ BO_ 2668068871  "Status bitfield";
CM_ BO_ 2668068870  "Fault bitfield";
CM_ BO_ 2668068867  "Current of phases U, V, W";
CM_ BO_ 2668068880  "Current of of the DC Bus";
CM_ BO_ 2668068878  "All AFEs will listen to this message";
CM_ BO_ 2668068875  "RMS Current of phases U, V, W";
CM_ BO_ 2668068876  "Three-Phase mains health (frequency, phase...)";
CM_ BO_ 2668068869  "Readouts of the module temperature sensors";
CM_ BO_ 2668068872  "Setpoints";
CM_ BO_ 2668068873  "Setpoints";
CM_ BO_ 2668036192  "Keep alive ping message. ";
CM_ BO_ 2668036160  "Operation Mode control: sets the converter operation mode";
CM_ BO_ 2668036176  "Fault Control: actions to clear faults and reset the system";
CM_ BO_ 2668036161  "Reactive power setpoint control.";
CM_ BO_ 2668036162  "PWM duty cycle control";
CM_ BO_ 2668036163  "Current setpoint control";
CM_ BO_ 2668036164  "Voltage setpoint control";
CM_ BO_ 2668036168  "Frequency setpoint control";
CM_ BO_ 2668036169  "Phase setpoint control";
CM_ BO_ 2668036208  "Additional voltage and current setpoints in single-phase rectifier and inverter control modes.";
CM_ BO_ 2668036165  "PFC stack control";
CM_ BO_ 2668036144  "Set the input and output voltage limits (minimum and maximum)";
CM_ BO_ 2668036145  "Set the output current limits (mminimum and maximum)";
CM_ BO_ 2668036172  "Set the Group ID of the device";
CM_ BO_ 2668068879  "Contains the Group ID of the device";
CM_ BO_ 2668036193  "Control the system flags";
CM_ BO_ 2668068896  "Current of phases A and B";
CM_ BO_ 2668068897  "Current of phases A and B";
CM_ BO_ 2668036170  "Automatic ADC calibration.";
CM_ BO_ 2668036171  "Setpoint for automatic ADC calibration.";
CM_ BO_ 2668036166  "Update of the calibration table for offsets.";
CM_ BO_ 2668036167  "Update of the calibration table for scales.";
CM_ BO_ 2668068945  "
                Adc scale (resolution) value of readouts.
            ";
CM_ BO_ 2668068946  "
                Adc fullscale value of readouts.
            ";
CM_ BO_ 2668068947  "
                Readout of ADC calibration data (offset) from EEPROM.
            ";
CM_ BO_ 2668068948  "
                Readout of ADC calibration data (gain) from EEPROM.
            ";
CM_ BO_ 2668068950  "Fault bitfield";

CM_ SG_ 2668068864 Device_type_31 "The device identification field, uniquely identifies the sender in the network";
CM_ SG_ 2668068864 HW_revision_31 "The hardware revision number";
CM_ SG_ 2668068864 HW_variant_31 "The DSP firmware revision number";
CM_ SG_ 2668068864 Stack_position_31 "Position of the module within the stack";
CM_ SG_ 2668068864 SN_number_31 "Unique module serial number";
CM_ SG_ 2668068865 FW_revision_0_31 "Character 0";
CM_ SG_ 2668068865 FW_revision_1_31 "Character 1";
CM_ SG_ 2668068865 FW_revision_2_31 "Character 2";
CM_ SG_ 2668068865 FW_revision_3_31 "Character 3";
CM_ SG_ 2668068865 FW_revision_4_31 "Character 3";
CM_ SG_ 2668068865 FW_revision_5_31 "Character 3";
CM_ SG_ 2668068865 FW_revision_6_31 "Character 3";
CM_ SG_ 2668068865 FW_revision_7_31 "Character 7";
CM_ SG_ 2668068865 FW_revision_8_31 "Character 8";
CM_ SG_ 2668068865 FW_revision_9_31 "Character 9";
CM_ SG_ 2668068865 FW_revision_10_31 "Character 10";
CM_ SG_ 2668068865 FW_revision_11_31 "Character 11";
CM_ SG_ 2668068865 FW_revision_12_31 "Character 12";
CM_ SG_ 2668068865 FW_revision_13_31 "Character 13";
CM_ SG_ 2668068865 FW_datecode_0_31 "Character 0";
CM_ SG_ 2668068865 FW_datecode_1_31 "Character 1";
CM_ SG_ 2668068865 FW_datecode_2_31 "Character 2";
CM_ SG_ 2668068865 FW_datecode_3_31 "Character 3";
CM_ SG_ 2668068865 FW_datecode_4_31 "Character 3";
CM_ SG_ 2668068865 FW_datecode_5_31 "Character 3";
CM_ SG_ 2668068865 FW_datecode_6_31 "Character 3";
CM_ SG_ 2668068865 FW_datecode_7_31 "Character 7";
CM_ SG_ 2668068865 FW_datecode_8_31 "Character 8";
CM_ SG_ 2668068865 FW_datecode_9_31 "Character 9";
CM_ SG_ 2668068865 FW_datecode_10_31 "Character 10";
CM_ SG_ 2668068865 FW_datecode_11_31 "Character 11";
CM_ SG_ 2668068865 FW_datecode_12_31 "Character 12";
CM_ SG_ 2668068865 FW_datecode_13_31 "Character 13";
CM_ SG_ 2668068877 FW_revision_0_31 "Character 0";
CM_ SG_ 2668068877 FW_revision_1_31 "Character 1";
CM_ SG_ 2668068877 FW_revision_2_31 "Character 2";
CM_ SG_ 2668068877 FW_revision_3_31 "Character 3";
CM_ SG_ 2668068877 FW_revision_4_31 "Character 3";
CM_ SG_ 2668068877 FW_revision_5_31 "Character 3";
CM_ SG_ 2668068877 FW_revision_6_31 "Character 3";
CM_ SG_ 2668068877 FW_revision_7_31 "Character 7";
CM_ SG_ 2668068877 FW_revision_8_31 "Character 8";
CM_ SG_ 2668068877 FW_revision_9_31 "Character 9";
CM_ SG_ 2668068877 FW_revision_10_31 "Character 10";
CM_ SG_ 2668068877 FW_revision_11_31 "Character 11";
CM_ SG_ 2668068877 FW_revision_12_31 "Character 12";
CM_ SG_ 2668068877 FW_revision_13_31 "Character 13";
CM_ SG_ 2668068877 FW_datecode_0_31 "Character 0";
CM_ SG_ 2668068877 FW_datecode_1_31 "Character 1";
CM_ SG_ 2668068877 FW_datecode_2_31 "Character 2";
CM_ SG_ 2668068877 FW_datecode_3_31 "Character 3";
CM_ SG_ 2668068877 FW_datecode_4_31 "Character 3";
CM_ SG_ 2668068877 FW_datecode_5_31 "Character 3";
CM_ SG_ 2668068877 FW_datecode_6_31 "Character 3";
CM_ SG_ 2668068877 FW_datecode_7_31 "Character 7";
CM_ SG_ 2668068877 FW_datecode_8_31 "Character 8";
CM_ SG_ 2668068877 FW_datecode_9_31 "Character 9";
CM_ SG_ 2668068877 FW_datecode_10_31 "Character 10";
CM_ SG_ 2668068877 FW_datecode_11_31 "Character 11";
CM_ SG_ 2668068877 FW_datecode_12_31 "Character 12";
CM_ SG_ 2668068877 FW_datecode_13_31 "Character 13";
CM_ SG_ 2668068866 Status_Error_Code_31 "Main status / error code as defined in errno/errno.h";
CM_ SG_ 2668068866 Data_1_31 "Additional information for the error/status";
CM_ SG_ 2668068866 Data_2_31 "Additional information for the error/status";
CM_ SG_ 2668068866 Data_3_31 "Additional information for the error/status";
CM_ SG_ 2668068871 Running_31 "Indicates if converter is running.";
CM_ SG_ 2668068871 PWM_31 "Indicates if converter is in PWM control mode.";
CM_ SG_ 2668068871 Current_dc_loop_mode_31 "Indicates if the current DC loop is enabled.";
CM_ SG_ 2668068871 Current_ac_loop_mode_31 "Indicates if the current AC loop is enabled.";
CM_ SG_ 2668068871 Buck_31 "Indicates if converter is in buck control mode.";
CM_ SG_ 2668068871 Boost_31 "Indicates if converter is in boost control mode.";
CM_ SG_ 2668068871 Precharge_dc_buck_mode_31 "Indicates if the precharge DC mode is enabled - buck direction.";
CM_ SG_ 2668068871 Precharge_dc_boost_mode_31 "Indicates if the precharge DC mode is enabled - boost direction.";
CM_ SG_ 2668068871 Rectifier_3ph_31 "Indicates if converter is in three-phase rectifier control mode.";
CM_ SG_ 2668068871 Stack_mode_31 "Indicates if converter is operating in stack mode.";
CM_ SG_ 2668068871 Master_31 "Indicates if converter is master in the stack.";
CM_ SG_ 2668068871 Slave_31 "Indicates if converter is slave in the stack.";
CM_ SG_ 2668068871 Inverter_1ph_31 "Indicates if converter is in single-phase inverter control mode.";
CM_ SG_ 2668068871 Boost_Neutral_31 "Indicates if converter is in boost control mode with neutral generation.";
CM_ SG_ 2668068871 Rectifier_1ph_31 "Indicates if converter is in single-phase rectifier control mode.";
CM_ SG_ 2668068871 Inverter_3ph_31 "Indicates if converter is in three-phase inverter control mode.";
CM_ SG_ 2668068871 Ready_31 "Indicates if converter is ready for operation.";
CM_ SG_ 2668068871 Inverter_1ph_Sync_31 "Single-phase inverter control mode with phase synchronization.";
CM_ SG_ 2668068871 Neutral_31 "Open-loop neutral generation.";
CM_ SG_ 2668068871 Rectifier_1ph_Buck_31 "Single-phase rectifier with buck on one leg.";
CM_ SG_ 2668068871 Inverter_1ph_Boost_31 "Single-phase inverter with boost on one leg.";
CM_ SG_ 2668068871 Rectifier_distributed_31 "Not available at the moment";
CM_ SG_ 2668068871 MPPT_buck_31 "Not available at the moment";
CM_ SG_ 2668068871 MPPT_boost_31 "Not available at the moment";
CM_ SG_ 2668068871 Buck_2p_float_31 "Buck in phases L1 and L2. Phase L3 is left floating (high impedance)";
CM_ SG_ 2668068871 Inverter_1ph_Distributed_31 "Single-phase inverter mode  distributed";
CM_ SG_ 2668068870 Protection_trip_internal_31 "This flagg is asserted if the interlock is open due to an internal fault condition (self-protection)";
CM_ SG_ 2668068870 Protection_trip_external_31 "This flag is asserted if the interlock is open due to an external condition received in the module.";
CM_ SG_ 2668068870 Phase_U_overcurrent_31 "Indicates an overcurrent event on Phase U. The overcurrent event is triggered when the measured phase current is over the programmed current limit.";
CM_ SG_ 2668068870 Phase_U_overvoltage_31 "Indicates an overvoltage event on Phase U. The overvoltage event is triggered when the measured phase voltage is over the programmed voltage limit.";
CM_ SG_ 2668068870 Phase_U_undervoltage_31 "Indicates an undervoltage event on Phase U. The overvoltage event is triggered when the measured phase voltage is over the programmed voltage limit.";
CM_ SG_ 2668068870 Phase_V_overvoltage_31 "Indicates an overvoltage event on Phase V. The overvoltage event is triggered when the measured phase voltage is over the programmed voltage limit.";
CM_ SG_ 2668068870 Phase_V_undervoltage_31 "Indicates an undervoltage event on Phase U. The overvoltage event is triggered when the measured phase voltage is over the programmed voltage limit.";
CM_ SG_ 2668068870 Phase_V_overcurrent_31 "Indicates an overcurrent event on Phase U. The overcurrent event is triggered when the measured phase current is over the programmed current limit.";
CM_ SG_ 2668068870 Phase_W_overvoltage_31 "Indicates an overvoltage event on Phase U. The overvoltage event is triggered when the measured phase voltage is over the programmed voltage limit.";
CM_ SG_ 2668068870 Phase_W_undervoltage_31 "Indicates an undervoltage event on Phase U. The overvoltage event is triggered when the measured phase voltage is over the programmed voltage limit.";
CM_ SG_ 2668068870 Phase_W_overcurrent_31 "Indicates an overcurrent event on Phase U. The overcurrent event is triggered when the measured phase current is over the programmed current limit.";
CM_ SG_ 2668068870 DC_undervoltage_31 "DC bus undervoltage condition. The undervoltage condition is asserted when the measured dc bus voltage is under the programmed voltage limit.";
CM_ SG_ 2668068870 DC_overvoltage_31 "DC bus overvoltage condition. The overvoltage condition is asserted when the measured dc bus voltage is over the programmed voltage limit.";
CM_ SG_ 2668068870 MOSFET_overtemperature_31 "This flag is asserted when the temperature of the MOSFET block is too high.";
CM_ SG_ 2668068870 Inductor_overtemperature_31 "This flag is asserted when the temperature of the inductor block is too high.";
CM_ SG_ 2668068870 Keep_Alive_not_served_31 "The Keep Alive feature is enabled but it was not served with the periodic message.";
CM_ SG_ 2668068870 PLL_not_locked_31 "Flag asserted when in rectifier modes, the PLL went out of lock condition";
CM_ SG_ 2668068870 Measurement_system_failure_31 "The voltages/currents measurement system is malfunctionning, and readouts are not guaranteed to be accurate.";
CM_ SG_ 2668068870 EEPROM_failure_31 "The configuration EEPROM failed to load or save the module configuration.";
CM_ SG_ 2668068867 Phase_U_31 "Phase current is the MOSFET loop current, in the branch U of the converter.";
CM_ SG_ 2668068867 Phase_V_31 "Phase current is the MOSFET loop current, in the branch V of the converter.";
CM_ SG_ 2668068867 Phase_W_31 "Phase current is the MOSFET loop current, in the branch W of the converter.";
CM_ SG_ 2668068880 Bus_current_31 "DC Bus current is possitive when current goes from input to output";
CM_ SG_ 2668068878 Phase_U_31 "Phase current is the MOSFET loop current, in the branch U of the converter.";
CM_ SG_ 2668068878 Phase_V_31 "Phase current is the MOSFET loop current, in the branch V of the converter.";
CM_ SG_ 2668068878 Phase_W_31 "Phase current is the MOSFET loop current, in the branch W of the converter.";
CM_ SG_ 2668068878 Stack_position_31 "Sender Stack position";
CM_ SG_ 2668068878 Group_ID_31 "Sender Group ID";
CM_ SG_ 2668068875 Phase_U_31 "RMS Phase current is the MOSFET loop current, in the branch U of the converter.";
CM_ SG_ 2668068875 Phase_V_31 "RMS Phase current is the MOSFET loop current, in the branch V of the converter.";
CM_ SG_ 2668068875 Phase_W_31 "RMS Phase current is the MOSFET loop current, in the branch W of the converter.";
CM_ SG_ 2668068876 Frequency_31 "Frequency of Three-Phase system";
CM_ SG_ 2668068876 Phase_31 "Phase of Three-Phase system";
CM_ SG_ 2668068869 Temp_Bridge_31 "Temperature of the MOSFET block";
CM_ SG_ 2668068869 Temp_Inductors_31 "Temperature of the inductors";
CM_ SG_ 2668068872 Phase_U_31 "The actual PWM duty cycle setpoint";
CM_ SG_ 2668068872 Phase_V_31 "The actual PWM duty cycle setpoint";
CM_ SG_ 2668068872 Phase_W_31 "The actual PWM duty cycle setpoint";
CM_ SG_ 2668068873 Current_setpoint_31 "The actual current setpoint";
CM_ SG_ 2668068873 Voltage_setpoint_31 "The actual voltage setpoint";
CM_ SG_ 2668068873 Frequency_setpoint_31 "The actual frequency setpoint";
CM_ SG_ 2668036192 Keep_Alive_Enable_31 "If set to 1, module will expect to receive this message every second repeatedly, or it will stop operation";
CM_ SG_ 2668036160 Converter_ON_31 "Enable the converter.";
CM_ SG_ 2668036160 PWM_ON_31 "Enable the PWM control mode.";
CM_ SG_ 2668036160 DC_Current_feedback_ON_31 "Enable the DC current loop";
CM_ SG_ 2668036160 AC_Current_feedback_ON_31 "Enable the AC current loop";
CM_ SG_ 2668036160 Buck_ON_31 "Enable the buck control mode.";
CM_ SG_ 2668036160 Boost_ON_31 "Enable the boost control mode.";
CM_ SG_ 2668036160 Rectifier_3ph_ON_31 "Enable the three-phase rectifier control mode.";
CM_ SG_ 2668036160 Inverter_1ph_ON_31 "Enable the single-phase inverter control mode.";
CM_ SG_ 2668036160 Rectifier_1ph_ON_31 "Enable the single-phase rectifier control mode.";
CM_ SG_ 2668036160 Boost_Neutral_ON_31 "Enable the boost control mode with neutral generation.";
CM_ SG_ 2668036160 Inverter_3ph_ON_31 "Enable the three-phase inverter control mode.";
CM_ SG_ 2668036160 Inverter_1ph_Sync_ON_31 "Single-phase inverter control mode with phase synchronization.";
CM_ SG_ 2668036160 Neutral_ON_31 "Open-loop neutral generation.";
CM_ SG_ 2668036160 Rectifier_1ph_Buck_ON_31 "Single-phase rectifier with buck on one leg.";
CM_ SG_ 2668036160 Inverter_1ph_Boost_ON_31 "Single-phase inverter with boost on one leg.";
CM_ SG_ 2668036160 Rectifier_Distributed_ON_31 "Single-phase (floating) distributed rectifier";
CM_ SG_ 2668036160 MPPT_buck_ON_31 "MPPT buck";
CM_ SG_ 2668036160 MPPT_boost_ON_31 "MPPT boost";
CM_ SG_ 2668036160 Buck_2p_float_ON_31 "Boost on L1 and L2. Floating L3 (high-impedance)";
CM_ SG_ 2668036160 Inverter_1ph_Distributed_ON_31 "Single-phase inverter mode distributed";
CM_ SG_ 2668036176 Clear_Interlock_31 "Clears the converter interlock";
CM_ SG_ 2668036176 Reset_Processor_31 "Reset the converter DSP";
CM_ SG_ 2668036176 Trip_Interlock_31 "Trip the inetrnal Interlock";
CM_ SG_ 2668036161 Reactive_current_setpoint_31 "This defines reactive current setpoint for 3-phase rectifier mode";
CM_ SG_ 2668036162 Phase_U_31 "The actual PWM duty cycle setpoint";
CM_ SG_ 2668036162 Phase_V_31 "The actual PWM duty cycle setpoint";
CM_ SG_ 2668036162 Phase_W_31 "The actual PWM duty cycle setpoint";
CM_ SG_ 2668036163 Current_setpoint_31 "Sets the output current setpoint. Active only when the current loop is enabled";
CM_ SG_ 2668036164 Voltage_setpoint_31 "Sets the output voltage setpoint. Active only when the voltage loop is enabled";
CM_ SG_ 2668036168 Frequency_setpoint_31 "Sets the frequency for single-phase and three-phase generator modes.";
CM_ SG_ 2668036169 Phase_setpoint_31 "Sets the phase for inverter control modes.";
CM_ SG_ 2668036165 Stack_position_31 "The converter position within the stack";
CM_ SG_ 2668036165 Stack_size_31 "How many PFC converters are in stack in total";
CM_ SG_ 2668036165 SN_number_31 "Unique module serial number";
CM_ SG_ 2668036144 Phase_voltage_min_31 "Minimum tolerated phase voltage";
CM_ SG_ 2668036144 Phase_voltage_max_31 "Maximum allowable phase voltage";
CM_ SG_ 2668036144 DC_voltage_min_31 "Minimum allowable dc voltage";
CM_ SG_ 2668036144 DC_voltage_max_31 "Maximum allowable dc voltage";
CM_ SG_ 2668036145 Phase_current_min_31 "Minimum allowable output current";
CM_ SG_ 2668036145 Phase_current_max_31 "Maximum allowable output current";
CM_ SG_ 2668036172 Group_ID_31 "Desired group ID for the device";
CM_ SG_ 2668068879 Group_ID_31 "Group ID of the device";
CM_ SG_ 2668036193 Factory_mode_31 "Customers MUST NOT USE this bit. If set to 1, module will enter in factory mode. ";
CM_ SG_ 2668036193 Silent_CAN_mode_31 "Customers MUST NOT USE this bit. If set to 1, module will enter in factory mode. ";
CM_ SG_ 2668036170 start_31 "Start automatic calibration. Multiplexer index must be 0!";
CM_ SG_ 2668036171 point_31 "Calibration point index.";
CM_ SG_ 2668036166 CRC_31 "Checksum of bytes 0 to 3, CRC-CCITT, corresponding to qChecksum (www.qt.io)";
CM_ SG_ 2668036167 CRC_31 "Checksum of bytes 0 to 3, CRC-CCITT, corresponding to qChecksum (www.qt.io)";
CM_ SG_ 2668068950 Current_U_High_31 "This flag is set if a hight current on U tripped the internal interlock";
CM_ SG_ 2668068950 Current_U_Low_31 "This flag is set if a low current on U tripped the internal interlock";
CM_ SG_ 2668068950 Current_V_High_31 "This flag is set if a hight current on V tripped the internal interlock";
CM_ SG_ 2668068950 Current_V_Low_31 "This flag is set if a low current on V tripped the internal interlock";
CM_ SG_ 2668068950 Current_W_High_31 "This flag is set if a hight current on W tripped the internal interlock";
CM_ SG_ 2668068950 Current_W_Low_31 "This flag is set if a low current on W tripped the internal interlock";
CM_ SG_ 2668068950 Voltage_DC_31 "This flag is set if a voltage on DC tripped the internal interlock";
CM_ SG_ 2668068950 Reboot_31 "This flag is set if a reboot tripped the internal interlock";
CM_ SG_ 2668068950 Unknown_31 "This flag the reason for the internal interlock is unknown";

BA_DEF_ BO_ "SystemMessageLongSymbol" STRING;

BA_ "SystemMessageLongSymbol" BO_ 2668036161 "AFE_Reactive_Current_Setpoint_Control_31";
BA_ "SystemMessageLongSymbol" BO_ 2668036168 "AFE_Frequency_Setpoint_Control_31";
BA_ "SystemMessageLongSymbol" BO_ 2668036208 "AFE_Rectifier_Setpoint_Control_31";
BA_ "SystemMessageLongSymbol" BO_ 2668036166 "_AFE_Calibration_Offset_Update_31";

VAL_ 2668068864 Device_type_31 7 "AFE";
VAL_ 2668068870 Protection_trip_internal_31 1 "fault";
VAL_ 2668068870 Protection_trip_external_31 1 "fault";
VAL_ 2668068870 Phase_U_overcurrent_31 1 "fault";
VAL_ 2668068870 Phase_U_overvoltage_31 1 "fault";
VAL_ 2668068870 Phase_U_undervoltage_31 1 "fault";
VAL_ 2668068870 Phase_V_overvoltage_31 1 "fault";
VAL_ 2668068870 Phase_V_undervoltage_31 1 "fault";
VAL_ 2668068870 Phase_V_overcurrent_31 1 "fault";
VAL_ 2668068870 Phase_W_overvoltage_31 1 "fault";
VAL_ 2668068870 Phase_W_undervoltage_31 1 "fault";
VAL_ 2668068870 Phase_W_overcurrent_31 1 "fault";
VAL_ 2668068870 DC_undervoltage_31 1 "fault";
VAL_ 2668068870 DC_overvoltage_31 1 "fault";
VAL_ 2668068870 MOSFET_overtemperature_31 1 "fault";
VAL_ 2668068870 Inductor_overtemperature_31 1 "fault";
VAL_ 2668068870 Keep_Alive_not_served_31 1 "fault";
VAL_ 2668068870 PLL_not_locked_31 1 "fault";
VAL_ 2668068870 NFO_31 1 "fault";
VAL_ 2668068870 Measurement_system_failure_31 1 "fault";
VAL_ 2668068870 EEPROM_failure_31 1 "fault";
VAL_ 2668068870 System_31 1 "fault";
VAL_ 2668068950 Current_U_High_31 1 "fault";
VAL_ 2668068950 Current_U_Low_31 1 "fault";
VAL_ 2668068950 Current_V_High_31 1 "fault";
VAL_ 2668068950 Current_V_Low_31 1 "fault";
VAL_ 2668068950 Current_W_High_31 1 "fault";
VAL_ 2668068950 Current_W_Low_31 1 "fault";
VAL_ 2668068950 Voltage_DC_31 1 "fault";
VAL_ 2668068950 Reboot_31 1 "fault";
VAL_ 2668068950 Unknown_31 1 "fault";
SIG_VALTYPE_ 2668068945 Current_U_31 : 1;
SIG_VALTYPE_ 2668068945 Current_V_31 : 1;
SIG_VALTYPE_ 2668068945 Current_W_31 : 1;
SIG_VALTYPE_ 2668068945 Voltage_U_31 : 1;
SIG_VALTYPE_ 2668068945 Voltage_V_31 : 1;
SIG_VALTYPE_ 2668068945 Voltage_W_31 : 1;
SIG_VALTYPE_ 2668068945 Voltage_DC_31 : 1;
SIG_VALTYPE_ 2668068946 Current_U_31 : 1;
SIG_VALTYPE_ 2668068946 Current_V_31 : 1;
SIG_VALTYPE_ 2668068946 Current_W_31 : 1;
SIG_VALTYPE_ 2668068946 Voltage_U_31 : 1;
SIG_VALTYPE_ 2668068946 Voltage_V_31 : 1;
SIG_VALTYPE_ 2668068946 Voltage_W_31 : 1;
SIG_VALTYPE_ 2668068946 Voltage_DC_31 : 1;
